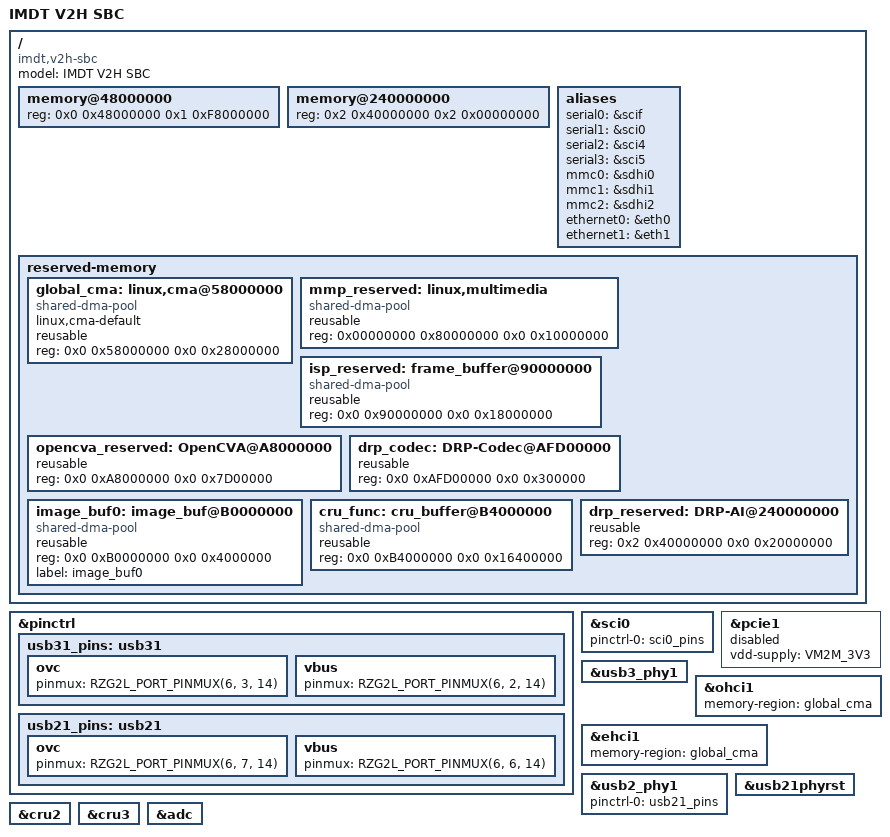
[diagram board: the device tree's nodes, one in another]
/dts-v1/;
#include "r9a09g057.dtsi"
#include <dt-bindings/pinctrl/rzg2l-pinctrl.h>
#include <dt-bindings/gpio/gpio.h>
#include "imdt-v2-sbc.dtsi"
/ {
	model = "IMDT V2H SBC";
	compatible = "imdt,v2h-sbc", "renesas,r9a09g057h4", "renesas,r9a09g057";

	memory@48000000 {
		device_type = "memory";
		/* first 128MB is reserved for secure area. */
		reg = <0x0 0x48000000 0x1 0xF8000000>;
	};

	memory@240000000 {
		device_type = "memory";
		reg = <0x2 0x40000000 0x2 0x00000000>;
	};
	
	aliases {
		serial0 = &scif;
		serial1 = &sci0;
		serial2 = &sci4;
		serial3 = &sci5;
		mmc0 = &sdhi0;
		mmc1 = &sdhi1;
		mmc2 = &sdhi2;
		ethernet0 = &eth0;
		ethernet1 = &eth1;
	};

	reserved-memory {
		#address-cells = <2>;
		#size-cells = <2>;
		ranges;

		global_cma: linux,cma@58000000 {
			compatible = "shared-dma-pool";
			linux,cma-default;
			reusable;
			reg = <0x0 0x58000000 0x0 0x28000000>;
		};

		mmp_reserved: linux,multimedia {
			compatible = "shared-dma-pool";
			reusable;
			reg = <0x00000000 0x80000000 0x0 0x10000000>;
		};

		isp_reserved: frame_buffer@90000000 {
			compatible = "shared-dma-pool";
			reusable;
			reg = <0x0 0x90000000 0x0 0x18000000>;
		};

		opencva_reserved: OpenCVA@A8000000 {
			reusable;
			reg = <0x0 0xA8000000 0x0 0x7D00000>;
		};

		drp_codec: DRP-Codec@AFD00000 {
			reusable;
			reg = <0x0 0xAFD00000 0x0 0x300000>;
		};

		image_buf0: image_buf@B0000000 {
			compatible = "shared-dma-pool";
			reusable;
			reg = <0x0 0xB0000000 0x0 0x4000000>;
			label = "image_buf0";
		};

		cru_func: cru_buffer@B4000000 {
			compatible = "shared-dma-pool";
			reusable;
			reg = <0x0 0xB4000000 0x0 0x16400000>;
		};

		drp_reserved: DRP-AI@240000000 {
			reusable;
			reg = <0x2 0x40000000 0x0 0x20000000>;
		};
	};

};

&pinctrl{

     usb31_pins: usb31 {
		ovc {
			pinmux = <RZG2L_PORT_PINMUX(6, 3, 14)>; /* OVC */
		};

		vbus {
			pinmux = <RZG2L_PORT_PINMUX(6, 2, 14)>; /* VBUS */
		};
	};

	usb21_pins: usb21 {
		ovc {
			pinmux = <RZG2L_PORT_PINMUX(6, 7, 14)>; /* OVC */
		};

		vbus {
			pinmux = <RZG2L_PORT_PINMUX(6, 6, 14)>; /* VBUS */
		};
	};
};

&sci0 {
	pinctrl-0 = <&sci0_pins>;
	pinctrl-names = "default";
	status = "okay";
};

&pcie1 {
	vdd-supply = <&VM2M_3V3>;
	status="disabled";
};

&usb3_phy1 {
	status = "okay";
};

// &xhci1 {
// 	pinctrl-0 = <&usb31_pins>;
// 	pinctrl-names = "default";
// 	memory-region = <&global_cma>;
// 	status = "okay";
// };

&ohci1 {
	memory-region = <&global_cma>;
	status = "okay";
};

&ehci1 {
	memory-region = <&global_cma>;
	status = "okay";
};

&usb2_phy1 {
	pinctrl-0 = <&usb21_pins>;
	pinctrl-names = "default";

	status = "okay";
};

&usb21phyrst {
	status = "okay";
};

&usb2_phy1 {
	pinctrl-0 = <&usb21_pins>;
	pinctrl-names = "default";
	status = "okay";
};

&cru2 {
	status = "okay";
};

&cru3 {
	status = "okay";
};

&adc {
	status = "okay";
};
